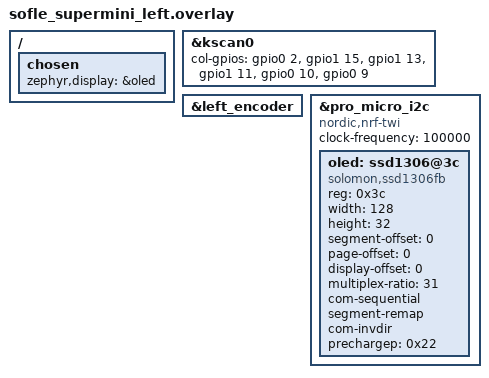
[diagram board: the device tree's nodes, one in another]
#include "sofle_supermini.dtsi"

/ {
    chosen {
        zephyr,display = &oled;
    };
};

&kscan0 {
    /* The left PCB footprint presents the physical columns mirrored to the SuperMini. Keep logical key order left-to-right. */
    col-gpios =
        <&gpio0 2 GPIO_ACTIVE_HIGH>,
        <&gpio1 15 GPIO_ACTIVE_HIGH>,
        <&gpio1 13 GPIO_ACTIVE_HIGH>,
        <&gpio1 11 GPIO_ACTIVE_HIGH>,
        <&gpio0 10 GPIO_ACTIVE_HIGH>,
        <&gpio0 9 GPIO_ACTIVE_HIGH>;
};

&left_encoder {
    status = "okay";
};

/* OLED is only present on the left half. Keeping it here (not in the shared
   .dtsi) prevents the right half's TWIM from probing 0x3c and hanging. */
&pro_micro_i2c {
    /* Use TWI (interrupt-driven) instead of the default TWIM (DMA) to avoid
       nRF52840 Anomaly 89: TWIM hangs permanently when SSD1306 NAKs during
       power-on reset, blocking ssd1306_init() forever and preventing ZMK boot. */
    compatible = "nordic,nrf-twi";
    status = "okay";
    clock-frequency = <100000>;

    oled: ssd1306@3c {
        compatible = "solomon,ssd1306fb";
        reg = <0x3c>;
        width = <128>;
        height = <32>;
        segment-offset = <0>;
        page-offset = <0>;
        display-offset = <0>;
        multiplex-ratio = <31>;
        /* 128x32 panels need sequential COM pin config (bit D4=0).
           Alternative (64-row) mode drives only the top row — seen as a white line. */
        com-sequential;
        segment-remap;
        com-invdir;
        prechargep = <0x22>;
    };
};
